CM_ "Toyota Yaris Hybrid 2014 (XP130, THS-II NoDSU) - reverse engineered from a candump (500kbps) captured on the";
CM_ "factory head-unit connector (28-pin, p/n 90980-12555, CAN-H=pin9/CAN-L=pin10), NOT the OBD-II diagnostic port.";
CM_ "Base messages taken from BogGyver/opendbc (tesla_unity_dev) toyota_nodsu_hybrid_pt_generated.dbc and empirically validated";
CM_ "against two independent real drive logs (re/data/logs/session_0044.log ~430s, session_0047.log ~440s). Additions for";
CM_ "BRAKE_ANALOG (0x224), COMBO_METER_0x34 (0x618), FUEL_COUNTER (0x3A0), HYBRID_STATUS/EV_DRIVE (0x498),";
CM_ "HV_BATTERY/BATTERY_SOC (0x4A7), ICE_RUNNING (0x245 b3.4) and PWR_DEMAND (0x320) are original findings from this";
CM_ "project, not present in opendbc.";
CM_ "See re/docs/signal_findings.md for full validation methodology and confidence levels.";

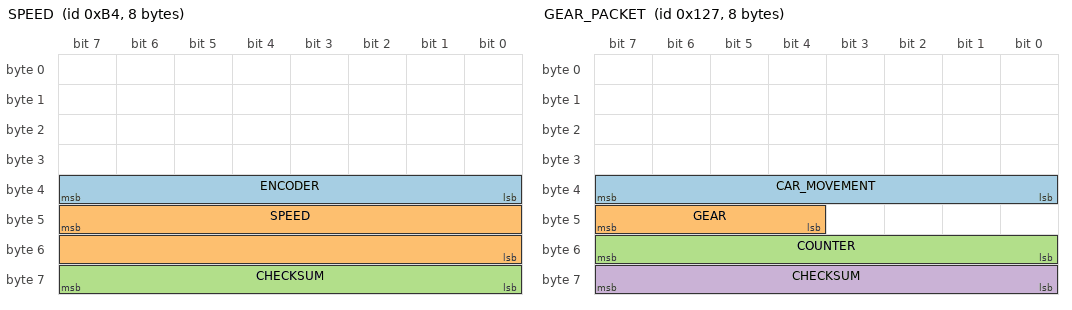
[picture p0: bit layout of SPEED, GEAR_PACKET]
BO_ 180 SPEED: 8 XXX
 SG_ ENCODER : 39|8@0+ (1,0) [0|255] "" XXX
 SG_ SPEED : 47|16@0+ (0.01,0) [0|250] "kph" XXX
 SG_ CHECKSUM : 63|8@0+ (1,0) [0|255] "" XXX

CM_ SG_ 180 SPEED "CONFIRMED. Validated against real 0->60->0 kph driving profile.";

BO_ 452 ENGINE_RPM: 8 XXX
 SG_ RPM : 7|16@0- (0.78125,0) [0|0] "rpm" XXX

CM_ SG_ 452 RPM "CONFIRMED. Oscillates 0/~1000-2000rpm matching ICE start/stop cycling typical of THS-II.";

BO_ 295 GEAR_PACKET: 8 XXX
 SG_ CAR_MOVEMENT : 39|8@0- (1,0) [0|255] "" XXX
 SG_ GEAR : 47|4@0+ (1,0) [0|15] "" XXX
 SG_ COUNTER : 55|8@0+ (1,0) [0|255] "" XXX
 SG_ CHECKSUM : 63|8@0+ (1,0) [0|255] "" XXX

VAL_ 295 GEAR 0 "P" 1 "R" 2 "N" 3 "D" 4 "B" ;
CM_ SG_ 295 GEAR "CONFIRMED, all 5 states observed across two independent logs: session_0044 shows a clean P(0)->R(1)->D(3) sequence with SPEED/BRAKE_PRESSED transitions lining up exactly with each shift; session_0047 adds N(2) and a full end-of-drive cycle through all five states including B (Engine Brake). CAR_MOVEMENT (byte4, signed) is a separate field in the same message, not part of the gear value.";

BO_ 560 BRAKE_MODULE2: 7 XXX
 SG_ BRAKE_PRESSED : 26|1@0+ (1,0) [0|1] "" XXX

CM_ SG_ 560 BRAKE_PRESSED "CONFIRMED. Transition timings correlate exactly with GEAR shifts and SPEED changes (brake held at standstill before/after each gear change).";

BO_ 548 BRAKE_ANALOG: 8 XXX
 SG_ BRAKE_VALUE : 32|16@0+ (1,0) [0|1023] "" XXX

CM_ BO_ 548 "STRONG HYPOTHESIS (not in any opendbc DBC). ID 0x224, ~41Hz. Formula: value = byte[4]<<8 | byte[5] (~10-bit, max observed 537). Median 0 while BRAKE_PRESSED=0 (n=12027) vs median 62 while pressed (n=5731); 99.99% of released samples <=5, 84% of pressed samples >5. Strong correlation confirms this is a brake pedal analog signal (pressure and/or position), but exact physical units/scale are NOT confirmed.";

BO_ 581 GAS_PEDAL: 8 XXX
 SG_ GAS_PEDAL : 23|8@0+ (0.005,0) [0|1] "" XXX
 SG_ ICE_RUNNING : 28|1@0+ (1,0) [0|1] "" XXX

CM_ SG_ 581 GAS_PEDAL "CONFIRMED. 0.0-0.35 (0-35%) range observed, closely tracking the accelerate/coast pattern of city driving and preceding each RPM/SPEED rise.";
CM_ SG_ 581 ICE_RUNNING "CONFIRMED on two independent logs. byte[3] bit4. 1 while the combustion engine is actually spinning (RPM>~800), 0 while stopped, INDEPENDENT of vehicle motion: 98-99% agreement with RPM(0x1C4)>50 across all four (moving/stopped x ICE on/off) states in both logs. Cleaner than thresholding RPM.";

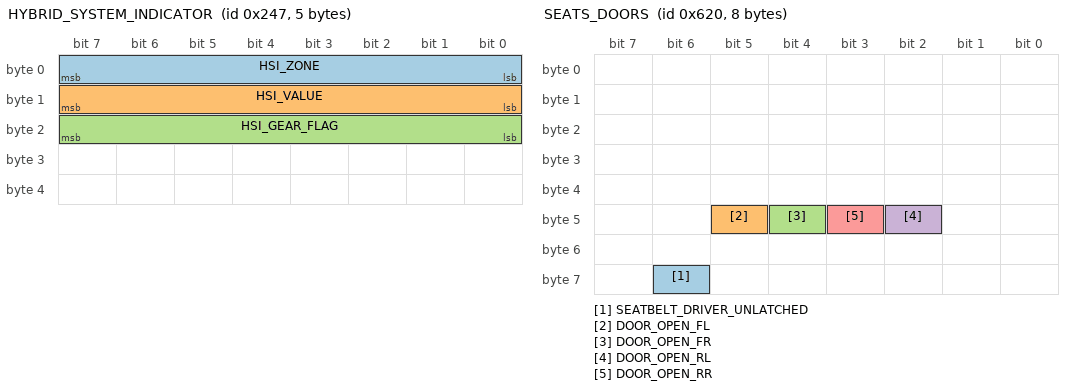
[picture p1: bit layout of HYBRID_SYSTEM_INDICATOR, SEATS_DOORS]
BO_ 583 HYBRID_SYSTEM_INDICATOR: 5 XXX
 SG_ HSI_ZONE : 7|8@0+ (1,0) [0|15] "" XXX
 SG_ HSI_VALUE : 15|8@0+ (1,0) [0|255] "%" XXX
 SG_ HSI_GEAR_FLAG : 23|8@0+ (1,0) [0|255] "" XXX

VAL_ 583 HSI_ZONE 4 "zero_in_gear" 6 "inactive_P_R" 12 "drive" 15 "charge" ;
VAL_ 583 HSI_GEAR_FLAG 50 "forward_gear" 255 "P_or_R" ;
CM_ BO_ 583 "CONFIRMED on two independent logs. ID 0x247, 42.5Hz, companion message of GAS_PEDAL (0x245). This is the dash CHG/ECO/PWR 'Hybrid System Indicator' value. HSI_VALUE (byte[1], sign per HSI_ZONE -- see SIGN NOTE below) = gauge position in percent of scale: 0 at standstill, +30..+47 at steady cruise (where the accel-like 0x320 byte4 sits at ~0 -- the discriminating test), up to +86/+94 observed under hard acceleration (full PWR = +100, never reached in these gentle drives), negative while coasting (-10..-19, light CHG) and braking, HARD-CLAMPED at -100 = full CHG. Always 0 in R and N, matching the real dash HSI which is inactive outside forward drive. HSI_ZONE (byte[0]): 12 on the PWR/ECO side, 15 on the CHG side, 4 when zero while in gear, 6 in P/R. HSI_GEAR_FLAG (byte[2]): 50 in forward gears, 255 in P/R. The exact ECO/PWR boundary is a fixed fraction of the positive scale on the real gauge (typically the top ~third); calibrate visually against the dash if pixel-exact zoning is needed. SIGN NOTE: HSI_ZONE, not HSI_VALUE's byte, carries the sign -- the two sides encode byte[1] differently and their raw ranges overlap. Zone 12 (PWR/ECO): byte[1] is an unsigned magnitude that sweeps past 155 under full throttle. Zone 15 (CHG): byte[1] is two's complement, hard-clamped at -100 (raw 156). Zones 4/6: always 0. The correlation is exact across both logs (n=32779). Inferring the sign from byte[1] alone -- either the DBC-nominal signed int8_t or the raw>=156 floor rule -- reads a hard-PWR value as deeply negative and swings the gauge to full CHG; confirmed on the car, hence the zone-based decode in firmware. DISPLAY NOTE: the dash halves the positive (PWR) value for display (PWR% = raw/2) because the ECO/PWR boundary (raw~100) is only the midpoint of the real gauge's PWR sweep, not its top -- see re/docs/signal_findings.md for the full caveat.";

BO_ 1090 CLIMATE_0x442: 8 XXX
 SG_ AMBIENT_TEMP : 7|8@0+ (1,-40) [-40|215] "degC" XXX

CM_ SG_ 1090 AMBIENT_TEMP "CONFIRMED. ID 0x442 (~2.5Hz, climate family 0x440/0x442/0x44D/0x45C), byte[0] - 40 = outside/ambient temperature in degC. The only byte that is quasi-constant (>95% single value) within each session but different across the two logs (raw 77 vs 67 -> 37degC vs 27degC); scale confirmed against the actual outside temperatures of the two capture days.";

BO_ 1553 UI_SETTING: 8 XXX
 SG_ UNITS : 26|2@0+ (1,0) [0|3] "" XXX
 SG_ ODOMETER : 43|20@0+ (1,0) [0|1048575] "" XXX

VAL_ 1553 UNITS 1 "km" 2 "miles" ;
CM_ SG_ 1553 ODOMETER "CONFIRMED but NOT remaining range. This is the TOTAL vehicle odometer (99552 -> 99555 km over the ~7min/~3km log, UNITS=km). No distance-to-empty / remaining-range signal was found on this bus -- see re/docs/signal_findings.md for the negative-result justification.";

BO_ 1556 STEERING_LEVERS: 8 XXX
 SG_ TURN_SIGNALS : 29|2@0+ (1,0) [0|3] "" XXX
 SG_ HAZARD_LIGHT : 27|1@0+ (1,0) [0|1] "" XXX

VAL_ 1556 TURN_SIGNALS 3 "none" 2 "right" 1 "left" ;
CM_ SG_ 1556 TURN_SIGNALS "CONFIRMED. All 3 states (left/right/none) observed over the drive with plausible multi-second durations consistent with real indicator usage at turns.";

BO_ 1568 SEATS_DOORS: 8 XXX
 SG_ SEATBELT_DRIVER_UNLATCHED : 62|1@0+ (1,0) [0|1] "" XXX
 SG_ DOOR_OPEN_FL : 45|1@0+ (1,0) [0|1] "" XXX
 SG_ DOOR_OPEN_FR : 44|1@0+ (1,0) [0|1] "" XXX
 SG_ DOOR_OPEN_RL : 42|1@0+ (1,0) [0|1] "" XXX
 SG_ DOOR_OPEN_RR : 43|1@0+ (1,0) [0|1] "" XXX

CM_ BO_ 1568 "CONFIRMED PRESENT, plausible (seatbelt toggles 0/1); doors never opened during this particular drive so DOOR_OPEN_* only show constant 0 in this log (not independently validated, but the message/bit layout is inherited verbatim from opendbc).";

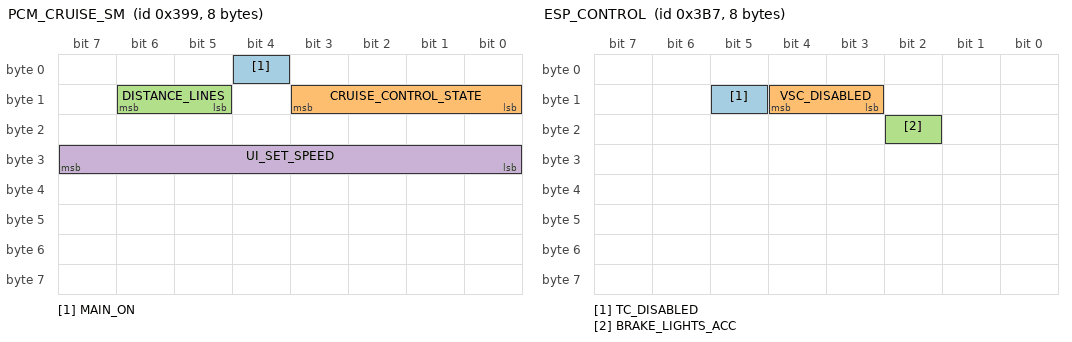
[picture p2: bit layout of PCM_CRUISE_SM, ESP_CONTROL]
BO_ 921 PCM_CRUISE_SM: 8 XXX
 SG_ MAIN_ON : 4|1@0+ (1,0) [0|1] "" XXX
 SG_ CRUISE_CONTROL_STATE : 11|4@0+ (1,0) [0|15] "" XXX
 SG_ DISTANCE_LINES : 14|2@0+ (1,0) [0|3] "" XXX
 SG_ UI_SET_SPEED : 31|8@0+ (1,0) [0|255] "" XXX

CM_ BO_ 921 "PRESENT but INACTIVE for the whole log (all-zero) -- cruise control was never engaged during capture, so fields could not be behaviourally validated beyond confirming the message exists at the expected ID/layout.";

BO_ 951 ESP_CONTROL: 8 XXX
 SG_ TC_DISABLED : 13|1@0+ (1,0) [0|1] "" XXX
 SG_ VSC_DISABLED : 12|2@0+ (1,0) [0|1] "" XXX
 SG_ BRAKE_LIGHTS_ACC : 18|1@0+ (1,0) [0|1] "" XXX

CM_ BO_ 951 "PRESENT but INACTIVE for the whole log (no VSC/TC intervention occurred during this calm drive).";

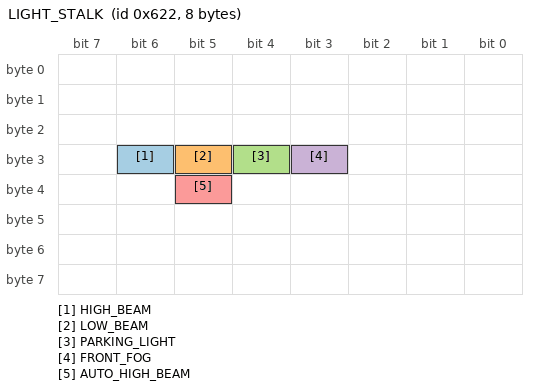
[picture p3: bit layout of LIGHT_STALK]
BO_ 1570 LIGHT_STALK: 8 XXX
 SG_ HIGH_BEAM : 30|1@0+ (1,0) [0|1] "" XXX
 SG_ LOW_BEAM : 29|1@0+ (1,0) [0|1] "" XXX
 SG_ PARKING_LIGHT : 28|1@0+ (1,0) [0|1] "" XXX
 SG_ FRONT_FOG : 27|1@0+ (1,0) [0|1] "" XXX
 SG_ AUTO_HIGH_BEAM : 37|1@0+ (1,0) [0|1] "" XXX

CM_ BO_ 1570 "CONFIRMED PRESENT; LOW_BEAM/PARKING_LIGHT toggled 0/1 during the log, plausible.";

BO_ 1560 COMBO_METER_0x34: 8 XXX
 SG_ TEMP_RAW : 24|8@0+ (1,0) [0|255] "" XXX

CM_ BO_ 1560 "STRONG HYPOTHESIS (not in any opendbc DBC). ID 0x618 belongs to a family of low-frequency (~0.1Hz) 'combination meter' multiplex messages (0x610-0x615, 0x618-0x61c). byte[3] (TEMP_RAW here) climbs monotonically and smoothly from 0 at cold start/idle to a plateau around 230-240 by t=350-430s, in lock-step with the engine running -- the textbook shape of an engine coolant warm-up curve reaching thermostat-regulated operating temperature after ~5 minutes. Candidate formula (UNCONFIRMED SCALE): temp_C = TEMP_RAW * 0.375, placing the plateau at a plausible 90 deg C; this scale factor is a best-fit guess, not derived from a reference thermometer reading. Could equally be transmission/CVT fluid temperature rather than coolant.";

BO_ 928 FUEL_COUNTER: 8 XXX
 SG_ FUEL_COUNTER_RAW : 63|8@0+ (1,0) [0|255] "" XXX

CM_ BO_ 928 "STRONG HYPOTHESIS (not in any opendbc DBC; NOT a fuel level gauge, see re/docs/signal_findings.md). ID 0x3A0 byte[7], only non-zero byte, 10Hz. Decrements correlate with ICE-ON RUNTIME (1 unit per ~20-25s of engine running, consistent to ~7% across both logs), not with wall time or distance; it even flickers 58<->59 while parked with the engine off. A 36L-tank level on a byte scale would deplete 15-20x slower than observed, so this is NOT the fuel gauge level, nor 'distance to empty' (km/unit via ODOMETER mismatches 7x between logs while time/unit is consistent to ~7%). Best hypothesis: a decrementing high-resolution fuel-consumed counter, quantum ~10-30mL, most likely the LOW BYTE of a wider register (would wrap 0->255 on a >=30min log -- logs so far are too short to confirm). Useful as instantaneous fuel consumption; do NOT use as absolute tank level.";

BO_ 953 TEMP_RAW2: 3 XXX
 SG_ TEMP2_RAW : 7|8@0+ (1,0) [0|255] "" XXX

CM_ BO_ 953 "STRONG HYPOTHESIS (not in any opendbc DBC). ID 0x3B9, dlc=3, byte[1] and byte[2] always 0x00 -- only byte[0] (TEMP2_RAW) is active, transmitted at ~1Hz. In both independent logs byte[0] climbs smoothly and nearly monotonically from a stable starting value early in the drive to a plateau late in the drive (session_0044: 103->173 over ~430s; session_0047: 110->160 over ~440s). Correlates very strongly with elapsed time (r=0.945/0.968) AND with the already-confirmed TEMP_RAW (0x618 byte3) warm-up curve (r=0.950/0.969), including a shared inflection point where both curves flatten out. Weak/negative correlation with instantaneous RPM (r=-0.16/-0.10) rules out a fast-responding signal and rules out battery voltage (which would sag in discharge and spike in regen, not climb monotonically); consistent with a second, more thermally-lagged temperature sensor -- candidate: engine oil, CVT/transaxle fluid, or HV battery pack. Plateau value differs between the two logs (173 vs 160), unlike coolant temp which is thermostat-regulated to a fixed setpoint. Not distinguishable from this data alone which physical sensor this is; no scale/formula proposed.";

BO_ 1186 CHASSIS_BRAKE2: 8 XXX
 SG_ BRAKE2_FIELD_A : 31|8@0+ (1,0) [0|255] "" XXX
 SG_ BRAKE2_FIELD_B : 47|8@0+ (1,0) [0|255] "" XXX

CM_ BO_ 1186 "TENTATIVE (not in any opendbc DBC) -- explicitly NOT a battery/SOC candidate despite superficially matching a charge/discharge pattern. ID 0x4A2, byte[3] (BRAKE2_FIELD_A) and byte[5] (BRAKE2_FIELD_B) both correlate strongly with the already-confirmed BRAKE_ANALOG (0x224 byte[4:6]): byte[3] r=-0.93/-0.79, byte[5] r=+0.93/+0.79 across the two logs -- far stronger than their correlation with GAS_PEDAL. Also correlates with SPEED (byte[3] r=+0.60/+0.22), which a pure battery-power signal would not be expected to do. Most likely a second brake/deceleration-related telemetry pair from a different ECU (e.g. ABS/VSC wheel-brake pressure), not battery power. Recorded here so this ID is not re-investigated as a false-lead SOC candidate.";

BO_ 1176 HYBRID_STATUS: 8 XXX
 SG_ EV_DRIVE : 47|1@0+ (1,0) [0|1] "" XXX

CM_ SG_ 1176 EV_DRIVE "CONFIRMED on two independent logs. byte[5] bit7. ON (100%) only while the vehicle is moving with the ICE stopped (pure electric propulsion, including regen); OFF while stopped even with ICE off (0-11% residual, hysteresis around standstill transitions) and OFF while driving with ICE running (3-9%, transition lag). Matches dash 'EV' indicator semantics; found by exhaustive per-bit agreement scan against the proxy RPM<50 AND speed>1 (23/23 and 5/5 proxy transitions matched). Redundant inverse 'ICE stopped' bits also validated: 0x49C byte[5] bit6 and 0x4AD byte[3] bit6. Message family 0x498-0x4AF exists in commaai opendbc toyota_2017_ref_pt.dbc as opaque CGW (gateway) data-recorder frames ENG1D50..ENG1D60 / DRENGxx, and is ABSENT on the non-hybrid 2010 Camry (TUCRRC analysis) -- a hybrid-powertrain-specific telemetry family.";

BO_ 1191 HV_BATTERY: 8 XXX
 SG_ BATTERY_SOC : 23|8@0+ (0.5,0) [0|100] "%" XXX

CM_ SG_ 1191 BATTERY_SOC "CONFIRMED on two independent logs (scale from Toyota convention). ID 0x4A7 (~2Hz, hybrid data-recorder family via gateway, see 0x498), byte[2] * 0.5 = HV battery SOC in %. Observed 54.0-71.5% (raw 108-143), matching the real THS-II NiMH operating band (~40-80%). A SOC is the *integral* of power flow rather than an instantaneous throttle-correlated value, so it was found by scoring each value change against expected battery physics instead: flat while parked, steady climb during stationary ICE warm-up charging, slow decline (~0.5% per 4-6s) during every EV stretch, recovery during every ICE-on/regen stretch, never wraps -- highest physics score of all 100 IDs on both logs (0.88/0.98). The 0.5%/bit resolution matches the known Techstream/Prius-Gen2 convention but is not yet verified against a reference tool reading; both logs happen to start at raw=108 (54.0%), possibly a power-on default during battery-ECU init. byte[7] of this message is constant 0xC8; bytes[0:2] form an unidentified signed 16-bit value (not MG rpm or battery current -- neither hypothesis fits).";
CM_ "0x612 byte[5]: excluded as SOC -- slow random walk centered on 128 with no charge/discharge physics, sign-flipping correlation with time between the two logs; byte[1] alternates 0x80/0x00 (heartbeat). Unidentified (possibly a 12V-battery current with offset 128). 0x4AE byte[7] (72-75, slowly rising in both logs): weak, unconfirmed candidate for HV battery/inverter temperature. 0x619 byte[6] and 0x63B byte[6]: also excluded (unstable/heartbeat-like).";

BO_ 800 PWR_DEMAND: 8 XXX
 SG_ ACCEL_DEMAND : 39|8@0- (1,0) [-128|127] "" XXX
 SG_ ACCEL_DEMAND_OFFSET_COPY : 63|8@0- (1,0) [-128|127] "" XXX

CM_ BO_ 800 "STRONG HYPOTHESIS on semantics, scale unconfirmed. ID 0x320, ~20Hz. byte[4] as signed 8-bit: positive under acceleration demand (+10..+31 with pedal), negative while braking/coasting (-8..-48), ~0 at rest AND at steady cruise -- a longitudinal acceleration/torque-demand-like quantity, NOT HV battery current (stays positive during EV traction and does not go negative during stationary charging; no true battery-current broadcast exists on this bus, and Prius-style 0x03B is absent). byte[7] tracks byte[4]+42 (same signal, constant offset); byte[5] is a {0,8} flag active only at standstill. Together with EV_DRIVE (0x498), ICE_RUNNING (0x245) and BATTERY_SOC (0x4A7), this fully explains how the Simplesoft RP5-TY-101 canbus box synthesizes its 'OilElectricityInfo' energy-flow display from pure passive listening -- no active diagnostic polling needed.";

CM_ "=== SIGNALS NOT ON THIS BUS (see re/docs/signal_findings.md for full explanation) ===";
CM_ "Remaining range / distance-to-empty (km): the only km counter is the 0x611 total odometer. Most likely computed inside the instrument cluster and never broadcast.";
CM_ "HV battery current/power (signed): Prius Gen2/Gen3-style 0x03B/0x3CB/0x3CD/0x529 IDs are all absent on this platform. Available only via solicited UDS (Mode 21) to the battery ECU.";
